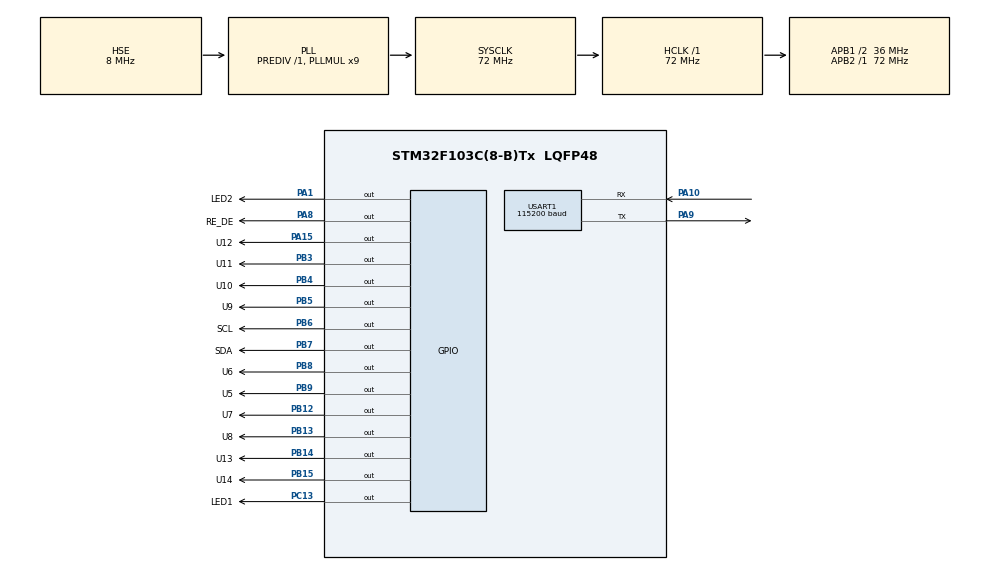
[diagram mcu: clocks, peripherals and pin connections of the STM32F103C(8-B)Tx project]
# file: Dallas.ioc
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Dma.Request0=USART1_RX
Dma.Request1=USART1_TX
Dma.USART1_RX.0.Direction=DMA_PERIPH_TO_MEMORY
Dma.USART1_RX.0.Instance=DMA1_Channel5
Dma.USART1_RX.0.MemDataAlignment=DMA_MDATAALIGN_BYTE
Dma.USART1_RX.0.MemInc=DMA_MINC_ENABLE
Dma.USART1_RX.0.Mode=DMA_NORMAL
Dma.USART1_RX.0.PeriphDataAlignment=DMA_PDATAALIGN_BYTE
Dma.USART1_RX.0.PeriphInc=DMA_PINC_DISABLE
Dma.USART1_RX.0.Priority=DMA_PRIORITY_LOW
Dma.USART1_TX.1.Direction=DMA_MEMORY_TO_PERIPH
Dma.USART1_TX.1.Instance=DMA1_Channel4
Dma.USART1_TX.1.MemDataAlignment=DMA_MDATAALIGN_BYTE
Dma.USART1_TX.1.MemInc=DMA_MINC_ENABLE
Dma.USART1_TX.1.Mode=DMA_NORMAL
Dma.USART1_TX.1.PeriphDataAlignment=DMA_PDATAALIGN_BYTE
Dma.USART1_TX.1.PeriphInc=DMA_PINC_DISABLE
Dma.USART1_TX.1.Priority=DMA_PRIORITY_LOW
FREERTOS.BinarySemaphores01=mbBinarySem,Dynamic,NULL;senorsSem,Dynamic,NULL
FREERTOS.INCLUDE_xSemaphoreGetMutexHolder=1
FREERTOS.Tasks01=mainTask,0,128,StartDefaultTask,Default,NULL,Dynamic,NULL,NULL;pollingTask,-3,128,StartTask02,Default,NULL,Dynamic,NULL,NULL
IWDG.Prescaler=IWDG_PRESCALER_256
Mcu.Family=STM32F1
Mcu.Name=STM32F103C(8-B)Tx
Mcu.Package=LQFP48
NVIC.DMA1_Channel4_IRQn=true\:5\:0\:false\:false\:true\:true\:false
NVIC.DMA1_Channel5_IRQn=true\:5\:0\:false\:false\:true\:true\:false
NVIC.PriorityGroup=NVIC_PRIORITYGROUP_4
NVIC.TIM4_IRQn=true\:0\:0\:false\:false\:true\:false\:false
NVIC.TimeBase=TIM4_IRQn
NVIC.TimeBaseIP=TIM4
NVIC.USART1_IRQn=true\:5\:0\:false\:false\:true\:true\:true
PA1.GPIO_Label=LED2
PA1.GPIO_ModeDefaultOutputPP=GPIO_MODE_OUTPUT_OD
PA1.GPIO_Speed=GPIO_SPEED_FREQ_LOW
PA1.PinState=GPIO_PIN_SET
PA1.Signal=GPIO_Output
PA10.GPIO_PuPd=GPIO_PULLUP
PA10.Mode=Multiprocessor_communication
PA10.Signal=USART1_RX
PA13.Mode=Serial_Wire
PA13.Signal=SYS_JTMS-SWDIO
PA14.Mode=Serial_Wire
PA14.Signal=SYS_JTCK-SWCLK
PA15.GPIO_Label=U12
PA15.GPIO_ModeDefaultOutputPP=GPIO_MODE_OUTPUT_OD
PA15.GPIO_PuPd=GPIO_PULLUP
PA15.GPIO_Speed=GPIO_SPEED_FREQ_HIGH
PA15.PinState=GPIO_PIN_SET
PA15.Signal=GPIO_Output
PA8.GPIO_Label=RE_DE
PA8.GPIO_ModeDefaultOutputPP=GPIO_MODE_OUTPUT_PP
PA8.GPIO_PuPd=GPIO_NOPULL
PA8.GPIO_Speed=GPIO_SPEED_FREQ_HIGH
PA8.PinState=GPIO_PIN_RESET
PA8.Signal=GPIO_Output
PA9.Mode=Multiprocessor_communication
PA9.Signal=USART1_TX
PB12.GPIO_Label=U7
PB12.GPIO_ModeDefaultOutputPP=GPIO_MODE_OUTPUT_OD
PB12.GPIO_PuPd=GPIO_PULLUP
PB12.GPIO_Speed=GPIO_SPEED_FREQ_HIGH
PB12.PinState=GPIO_PIN_SET
PB12.Signal=GPIO_Output
PB13.GPIO_Label=U8
PB13.GPIO_ModeDefaultOutputPP=GPIO_MODE_OUTPUT_OD
PB13.GPIO_PuPd=GPIO_PULLUP
PB13.GPIO_Speed=GPIO_SPEED_FREQ_HIGH
PB13.PinState=GPIO_PIN_SET
PB13.Signal=GPIO_Output
PB14.GPIO_Label=U13
PB14.GPIO_ModeDefaultOutputPP=GPIO_MODE_OUTPUT_OD
PB14.GPIO_PuPd=GPIO_PULLUP
PB14.GPIO_Speed=GPIO_SPEED_FREQ_HIGH
PB14.PinState=GPIO_PIN_SET
PB14.Signal=GPIO_Output
PB15.GPIO_Label=U14
PB15.GPIO_ModeDefaultOutputPP=GPIO_MODE_OUTPUT_OD
PB15.GPIO_PuPd=GPIO_PULLUP
PB15.GPIO_Speed=GPIO_SPEED_FREQ_HIGH
PB15.PinState=GPIO_PIN_SET
PB15.Signal=GPIO_Output
PB3.GPIO_Label=U11
PB3.GPIO_ModeDefaultOutputPP=GPIO_MODE_OUTPUT_OD
PB3.GPIO_PuPd=GPIO_PULLUP
PB3.GPIO_Speed=GPIO_SPEED_FREQ_HIGH
PB3.PinState=GPIO_PIN_SET
PB3.Signal=GPIO_Output
PB4.GPIO_Label=U10
PB4.GPIO_ModeDefaultOutputPP=GPIO_MODE_OUTPUT_OD
PB4.GPIO_PuPd=GPIO_PULLUP
PB4.GPIO_Speed=GPIO_SPEED_FREQ_HIGH
PB4.PinState=GPIO_PIN_SET
PB4.Signal=GPIO_Output
PB5.GPIO_Label=U9
PB5.GPIO_ModeDefaultOutputPP=GPIO_MODE_OUTPUT_OD
PB5.GPIO_PuPd=GPIO_PULLUP
PB5.GPIO_Speed=GPIO_SPEED_FREQ_HIGH
PB5.PinState=GPIO_PIN_SET
PB5.Signal=GPIO_Output
PB6.GPIO_Label=SCL
PB6.GPIO_ModeDefaultOutputPP=GPIO_MODE_OUTPUT_OD
PB6.GPIO_PuPd=GPIO_PULLUP
PB6.GPIO_Speed=GPIO_SPEED_FREQ_HIGH
PB6.PinState=GPIO_PIN_SET
PB6.Signal=GPIO_Output
PB7.GPIO_Label=SDA
PB7.GPIO_ModeDefaultOutputPP=GPIO_MODE_OUTPUT_OD
PB7.GPIO_PuPd=GPIO_PULLUP
PB7.GPIO_Speed=GPIO_SPEED_FREQ_HIGH
PB7.PinState=GPIO_PIN_SET
PB7.Signal=GPIO_Output
PB8.GPIO_Label=U6
PB8.GPIO_ModeDefaultOutputPP=GPIO_MODE_OUTPUT_OD
PB8.GPIO_PuPd=GPIO_PULLUP
PB8.GPIO_Speed=GPIO_SPEED_FREQ_HIGH
PB8.PinState=GPIO_PIN_SET
PB8.Signal=GPIO_Output
PB9.GPIO_Label=U5
PB9.GPIO_ModeDefaultOutputPP=GPIO_MODE_OUTPUT_OD
PB9.GPIO_PuPd=GPIO_PULLUP
PB9.GPIO_Speed=GPIO_SPEED_FREQ_HIGH
PB9.PinState=GPIO_PIN_SET
PB9.Signal=GPIO_Output
PC13-TAMPER-RTC.GPIO_Label=LED1
PC13-TAMPER-RTC.GPIO_Speed=GPIO_SPEED_FREQ_LOW
PC13-TAMPER-RTC.PinState=GPIO_PIN_SET
PC13-TAMPER-RTC.Signal=GPIO_Output
PD0-OSC_IN.Mode=HSE-External-Oscillator
PD0-OSC_IN.Signal=RCC_OSC_IN
PD1-OSC_OUT.Mode=HSE-External-Oscillator
PD1-OSC_OUT.Signal=RCC_OSC_OUT
ProjectManager.HeapSize=0x10
ProjectManager.StackSize=0x200
ProjectManager.TargetToolchain=EWARM
RCC.AHBFreq_Value=72000000
RCC.APB1CLKDivider=RCC_HCLK_DIV2
RCC.APB1Freq_Value=36000000
RCC.APB1TimFreq_Value=72000000
RCC.APB2Freq_Value=72000000
RCC.APB2TimFreq_Value=72000000
RCC.HCLKFreq_Value=72000000
RCC.PLLMUL=RCC_PLL_MUL9
RCC.PLLSourceVirtual=RCC_PLLSOURCE_HSE
RCC.SYSCLKFreq_VALUE=72000000
RCC.SYSCLKSource=RCC_SYSCLKSOURCE_PLLCLK
RCC.USBFreq_Value=72000000
USART1.BaudRate=115200
USART1.VirtualMode=VM_ASYNC
USART1.WakeUpMethode=UART_WAKEUPMETHOD_IDLELINE
VP_FREERTOS_VS_ENABLE.Mode=Enabled
VP_IWDG_VS_IWDG.Mode=IWDG_Activate
VP_SYS_VS_tim4.Mode=TIM4
board=custom

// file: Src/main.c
/**
  ******************************************************************************
  * @file           : main.c
  * @brief          : Main program body
  ******************************************************************************
  * This notice applies to any and all portions of this file
  * that are not between comment pairs USER CODE BEGIN and
  * USER CODE END. Other portions of this file, whether
  * inserted by the user or by software development tools
  * are owned by their respective copyright owners.
  *
  * Copyright (c) 2019 STMicroelectronics International N.V.
  * All rights reserved.
  *
  * Redistribution and use in source and binary forms, with or without
  * modification, are permitted, provided that the following conditions are met:
  *
  * 1. Redistribution of source code must retain the above copyright notice,
  *    this list of conditions and the following disclaimer.
  * 2. Redistributions in binary form must reproduce the above copyright notice,
  *    this list of conditions and the following disclaimer in the documentation
  *    and/or other materials provided with the distribution.
  * 3. Neither the name of STMicroelectronics nor the names of other
  *    contributors to this software may be used to endorse or promote products
  *    derived from this software without specific written permission.
  * 4. This software, including modifications and/or derivative works of this
  *    software, must execute solely and exclusively on microcontroller or
  *    microprocessor devices manufactured by or for STMicroelectronics.
  * 5. Redistribution and use of this software other than as permitted under
  *    this license is void and will automatically terminate your rights under
  *    this license.
  *
  * THIS SOFTWARE IS PROVIDED BY STMICROELECTRONICS AND CONTRIBUTORS "AS IS"
  * AND ANY EXPRESS, IMPLIED OR STATUTORY WARRANTIES, INCLUDING, BUT NOT
  * LIMITED TO, THE IMPLIED WARRANTIES OF MERCHANTABILITY, FITNESS FOR A
  * PARTICULAR PURPOSE AND NON-INFRINGEMENT OF THIRD PARTY INTELLECTUAL PROPERTY
  * RIGHTS ARE DISCLAIMED TO THE FULLEST EXTENT PERMITTED BY LAW. IN NO EVENT
  * SHALL STMICROELECTRONICS OR CONTRIBUTORS BE LIABLE FOR ANY DIRECT, INDIRECT,
  * INCIDENTAL, SPECIAL, EXEMPLARY, OR CONSEQUENTIAL DAMAGES (INCLUDING, BUT NOT
  * LIMITED TO, PROCUREMENT OF SUBSTITUTE GOODS OR SERVICES; LOSS OF USE, DATA,
  * OR PROFITS; OR BUSINESS INTERRUPTION) HOWEVER CAUSED AND ON ANY THEORY OF
  * LIABILITY, WHETHER IN CONTRACT, STRICT LIABILITY, OR TORT (INCLUDING
  * NEGLIGENCE OR OTHERWISE) ARISING IN ANY WAY OUT OF THE USE OF THIS SOFTWARE,
  * EVEN IF ADVISED OF THE POSSIBILITY OF SUCH DAMAGE.
  *
  ******************************************************************************
  */
#include "main.h"
#include "stm32f1xx_hal.h"
#include "cmsis_os.h"

/* USER CODE BEGIN Includes */
#include "modbus.h"
extern modbus_t modbus;

/* USER CODE END Includes */

IWDG_HandleTypeDef hiwdg;

UART_HandleTypeDef huart1;
DMA_HandleTypeDef hdma_usart1_rx;
DMA_HandleTypeDef hdma_usart1_tx;

osThreadId mainTaskHandle;
osThreadId pollingTaskHandle;
osSemaphoreId mbBinarySemHandle;
osSemaphoreId senorsSemHandle;

/* USER CODE BEGIN PV */
/* Private variables ---------------------------------------------------------*/

/* USER CODE END PV */

void SystemClock_Config(void);
static void MX_GPIO_Init(void);
static void MX_DMA_Init(void);
static void MX_IWDG_Init(void);
static void MX_USART1_UART_Init(void);
void StartDefaultTask(void const * argument);
void StartTask02(void const * argument);

/* USER CODE BEGIN PFP */
/* Private function prototypes -----------------------------------------------*/

/* USER CODE END PFP */

int main(void)
{

  /* MCU Configuration----------------------------------------------------------*/

  /* Reset of all peripherals, Initializes the Flash interface and the Systick. */
  HAL_Init();

  /* Configure the system clock */
  SystemClock_Config();

  /* Initialize all configured peripherals */
  MX_GPIO_Init();
  MX_DMA_Init();
  MX_IWDG_Init();
  MX_USART1_UART_Init();

  /* Create the semaphores(s) */
  /* definition and creation of mbBinarySem */
  osSemaphoreDef(mbBinarySem);
  mbBinarySemHandle = osSemaphoreCreate(osSemaphore(mbBinarySem), 1);

  /* definition and creation of senorsSem */
  osSemaphoreDef(senorsSem);
  senorsSemHandle = osSemaphoreCreate(osSemaphore(senorsSem), 1);

  /* Create the thread(s) */
  /* definition and creation of mainTask */
  osThreadDef(mainTask, StartDefaultTask, osPriorityNormal, 0, 128);
  mainTaskHandle = osThreadCreate(osThread(mainTask), NULL);

  /* definition and creation of pollingTask */
  osThreadDef(pollingTask, StartTask02, osPriorityIdle, 0, 128);
  pollingTaskHandle = osThreadCreate(osThread(pollingTask), NULL);

  /* Start scheduler */
  osKernelStart();

  /* We should never get here as control is now taken by the scheduler */

  /* Infinite loop */
  while (1)
  {

  }

}

void SystemClock_Config(void)
{

  RCC_OscInitTypeDef RCC_OscInitStruct;
  RCC_ClkInitTypeDef RCC_ClkInitStruct;

    /**Initializes the CPU, AHB and APB busses clocks
    */
  RCC_OscInitStruct.OscillatorType = RCC_OSCILLATORTYPE_LSI|RCC_OSCILLATORTYPE_HSE;
  RCC_OscInitStruct.HSEState = RCC_HSE_ON;
  RCC_OscInitStruct.HSEPredivValue = RCC_HSE_PREDIV_DIV1;
  RCC_OscInitStruct.HSIState = RCC_HSI_ON;
  RCC_OscInitStruct.LSIState = RCC_LSI_ON;
  RCC_OscInitStruct.PLL.PLLState = RCC_PLL_ON;
  RCC_OscInitStruct.PLL.PLLSource = RCC_PLLSOURCE_HSE;
  RCC_OscInitStruct.PLL.PLLMUL = RCC_PLL_MUL9;
  if (HAL_RCC_OscConfig(&RCC_OscInitStruct) != HAL_OK)
  {
    _Error_Handler(__FILE__, __LINE__);
  }

    /**Initializes the CPU, AHB and APB busses clocks
    */
  RCC_ClkInitStruct.ClockType = RCC_CLOCKTYPE_HCLK|RCC_CLOCKTYPE_SYSCLK
                              |RCC_CLOCKTYPE_PCLK1|RCC_CLOCKTYPE_PCLK2;
  RCC_ClkInitStruct.SYSCLKSource = RCC_SYSCLKSOURCE_PLLCLK;
  RCC_ClkInitStruct.AHBCLKDivider = RCC_SYSCLK_DIV1;
  RCC_ClkInitStruct.APB1CLKDivider = RCC_HCLK_DIV2;
  RCC_ClkInitStruct.APB2CLKDivider = RCC_HCLK_DIV1;

  if (HAL_RCC_ClockConfig(&RCC_ClkInitStruct, FLASH_LATENCY_2) != HAL_OK)
  {
    _Error_Handler(__FILE__, __LINE__);
  }

    /**Configure the Systick interrupt time
    */
  HAL_SYSTICK_Config(HAL_RCC_GetHCLKFreq()/1000);

    /**Configure the Systick
    */
  HAL_SYSTICK_CLKSourceConfig(SYSTICK_CLKSOURCE_HCLK);

  /* SysTick_IRQn interrupt configuration */
  HAL_NVIC_SetPriority(SysTick_IRQn, 15, 0);
}

/* IWDG init function */
static void MX_IWDG_Init(void)
{

  hiwdg.Instance = IWDG;
  hiwdg.Init.Prescaler = IWDG_PRESCALER_256;
  hiwdg.Init.Reload = 4095;
  if (HAL_IWDG_Init(&hiwdg) != HAL_OK)
  {
    _Error_Handler(__FILE__, __LINE__);
  }

}

/* USART1 init function */
static void MX_USART1_UART_Init(void)
{

  huart1.Instance = USART1;
  huart1.Init.BaudRate = 115200;
  huart1.Init.WordLength = UART_WORDLENGTH_8B;
  huart1.Init.StopBits = UART_STOPBITS_1;
  huart1.Init.Parity = UART_PARITY_NONE;
  huart1.Init.Mode = UART_MODE_TX_RX;
  huart1.Init.HwFlowCtl = UART_HWCONTROL_NONE;
  huart1.Init.OverSampling = UART_OVERSAMPLING_16;
  if (HAL_MultiProcessor_Init(&huart1, 0, UART_WAKEUPMETHOD_IDLELINE) != HAL_OK)
  {
    _Error_Handler(__FILE__, __LINE__);
  }

}

static void MX_DMA_Init(void)
{
  /* DMA controller clock enable */
  __HAL_RCC_DMA1_CLK_ENABLE();

  /* DMA interrupt init */
  /* DMA1_Channel4_IRQn interrupt configuration */
  HAL_NVIC_SetPriority(DMA1_Channel4_IRQn, 5, 0);
  HAL_NVIC_EnableIRQ(DMA1_Channel4_IRQn);
  /* DMA1_Channel5_IRQn interrupt configuration */
  HAL_NVIC_SetPriority(DMA1_Channel5_IRQn, 5, 0);
  HAL_NVIC_EnableIRQ(DMA1_Channel5_IRQn);

}

/** Configure pins as
        * Analog
        * Input
        * Output
        * EVENT_OUT
        * EXTI
*/
static void MX_GPIO_Init(void)
{

  GPIO_InitTypeDef GPIO_InitStruct;

  /* GPIO Ports Clock Enable */
  __HAL_RCC_GPIOC_CLK_ENABLE();
  __HAL_RCC_GPIOD_CLK_ENABLE();
  __HAL_RCC_GPIOA_CLK_ENABLE();
  __HAL_RCC_GPIOB_CLK_ENABLE();

  /*Configure GPIO pin Output Level */
  HAL_GPIO_WritePin(LED1_GPIO_Port, LED1_Pin, GPIO_PIN_SET);

  /*Configure GPIO pin Output Level */
  HAL_GPIO_WritePin(GPIOA, LED2_Pin|U12_Pin, GPIO_PIN_SET);

  /*Configure GPIO pin Output Level */
  HAL_GPIO_WritePin(GPIOB, U7_Pin|U8_Pin|U13_Pin|U14_Pin
                          |U11_Pin|U10_Pin|U9_Pin|SCL_Pin
                          |SDA_Pin|U6_Pin|U5_Pin, GPIO_PIN_SET);

  /*Configure GPIO pin Output Level */
  HAL_GPIO_WritePin(RE_DE_GPIO_Port, RE_DE_Pin, GPIO_PIN_RESET);

  /*Configure GPIO pin : LED1_Pin */
  GPIO_InitStruct.Pin = LED1_Pin;
  GPIO_InitStruct.Mode = GPIO_MODE_OUTPUT_PP;
  GPIO_InitStruct.Pull = GPIO_NOPULL;
  GPIO_InitStruct.Speed = GPIO_SPEED_FREQ_LOW;
  HAL_GPIO_Init(LED1_GPIO_Port, &GPIO_InitStruct);

  /*Configure GPIO pin : LED2_Pin */
  GPIO_InitStruct.Pin = LED2_Pin;
  GPIO_InitStruct.Mode = GPIO_MODE_OUTPUT_OD;
  GPIO_InitStruct.Pull = GPIO_NOPULL;
  GPIO_InitStruct.Speed = GPIO_SPEED_FREQ_LOW;
  HAL_GPIO_Init(LED2_GPIO_Port, &GPIO_InitStruct);

  /*Configure GPIO pins : U7_Pin U8_Pin U13_Pin U14_Pin
                           U11_Pin U10_Pin U9_Pin SCL_Pin
                           SDA_Pin U6_Pin U5_Pin */
  GPIO_InitStruct.Pin = U7_Pin|U8_Pin|U13_Pin|U14_Pin
                          |U11_Pin|U10_Pin|U9_Pin|SCL_Pin
                          |SDA_Pin|U6_Pin|U5_Pin;
  GPIO_InitStruct.Mode = GPIO_MODE_OUTPUT_OD;
  GPIO_InitStruct.Pull = GPIO_PULLUP;
  GPIO_InitStruct.Speed = GPIO_SPEED_FREQ_HIGH;
  HAL_GPIO_Init(GPIOB, &GPIO_InitStruct);

  /*Configure GPIO pin : RE_DE_Pin */
  GPIO_InitStruct.Pin = RE_DE_Pin;
  GPIO_InitStruct.Mode = GPIO_MODE_OUTPUT_PP;
  GPIO_InitStruct.Pull = GPIO_NOPULL;
  GPIO_InitStruct.Speed = GPIO_SPEED_FREQ_HIGH;
  HAL_GPIO_Init(RE_DE_GPIO_Port, &GPIO_InitStruct);

  /*Configure GPIO pin : U12_Pin */
  GPIO_InitStruct.Pin = U12_Pin;
  GPIO_InitStruct.Mode = GPIO_MODE_OUTPUT_OD;
  GPIO_InitStruct.Pull = GPIO_PULLUP;
  GPIO_InitStruct.Speed = GPIO_SPEED_FREQ_HIGH;
  HAL_GPIO_Init(U12_GPIO_Port, &GPIO_InitStruct);

}

/* StartDefaultTask function */
void StartDefaultTask(void const * argument)
{

  /* USER CODE BEGIN 5 */
   initTaskMain();
   initTaskPolling();
   vTaskResume(pollingTaskHandle);
  /* Infinite loop */
  for(;;)
  {
    processTaskMain();
    osDelay(1);
  }
  /* USER CODE END 5 */
}

/* StartTask02 function */
void StartTask02(void const * argument)
{
  /* USER CODE BEGIN StartTask02 */
  vTaskSuspend(pollingTaskHandle);
    /* Infinite loop */
  for(;;)
  {
      processTaskPolling();
      osDelay(1);
  }
  /* USER CODE END StartTask02 */
}

void HAL_TIM_PeriodElapsedCallback(TIM_HandleTypeDef *htim)
{
  if (htim->Instance == TIM4) {
    HAL_IncTick();
  }
}

void _Error_Handler(char *file, int line)
{
  while(1)
  {
  }
}

/************************ (C) COPYRIGHT STMicroelectronics *****END OF FILE****/
